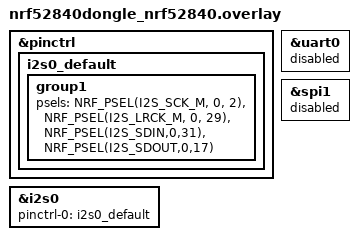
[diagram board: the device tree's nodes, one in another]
&pinctrl {
	i2s0_default: i2s0_default {
		group1 {
			psels = <NRF_PSEL(I2S_SCK_M, 0, 2)>,
				<NRF_PSEL(I2S_LRCK_M, 0, 29)>,
				<NRF_PSEL(I2S_SDIN,0,31)>,
				<NRF_PSEL(I2S_SDOUT,0,17)>;
		};
	};
};


&i2s0{
	status = "okay";
	pinctrl-0 = <&i2s0_default>;
	pinctrl-names = "default";
	};

//Below are disabled since 2 of those pins are configured for them
&uart0 {
	status="disabled";
};

&spi1{
	status="disabled";
};
